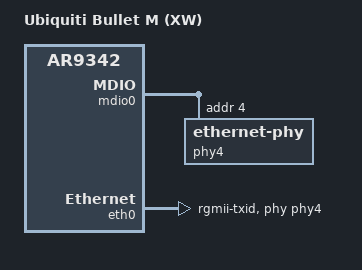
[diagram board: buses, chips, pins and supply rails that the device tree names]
// SPDX-License-Identifier: GPL-2.0-or-later OR MIT

#include "ar9342_ubnt_xw.dtsi"

/ {
	compatible = "ubnt,bullet-m-xw", "ubnt,xw", "qca,ar9342";
	model = "Ubiquiti Bullet M (XW)";
};

&mdio0 {
	status = "okay";

	phy4: ethernet-phy@4 {
		reg = <4>;
		max-speed = <100>;
	};
};

&eth0 {
	status = "okay";

	phy-mode = "rgmii-txid";
	phy-handle = <&phy4>;

	gmac-config {
		device = <&gmac>;
		rxd-delay = <3>;
		rxdv-delay = <3>;
	};
};
